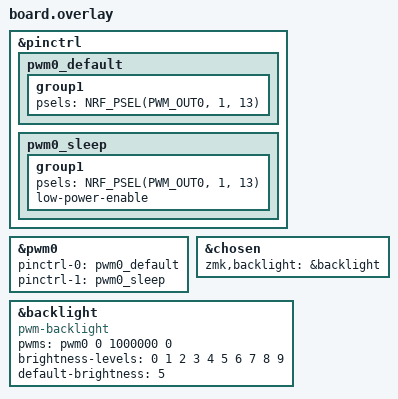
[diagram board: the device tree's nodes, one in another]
&pinctrl {
    // Other pinctrl definitions for other hardware
    pwm0_default: pwm0_default {
        group1 {
            psels = <NRF_PSEL(PWM_OUT0, 1, 13)>;
        };
    };
    pwm0_sleep: pwm0_sleep {
        group1 {
            psels = <NRF_PSEL(PWM_OUT0, 1, 13)>;
            low-power-enable;
        };
    };
};

&pwm0 {
    status = "okay";
    pinctrl-0 = <&pwm0_default>;
    pinctrl-1 = <&pwm0_sleep>;
    pinctrl-names = "default", "sleep";
};

&chosen {
    zmk,backlight = &backlight;
};

&backlight {
    compatible = "pwm-backlight";
    pwms = <&pwm0 0 1000000 0>;
    brightness-levels = <0 1 2 3 4 5 6 7 8 9>;
    default-brightness = <5>;
};
